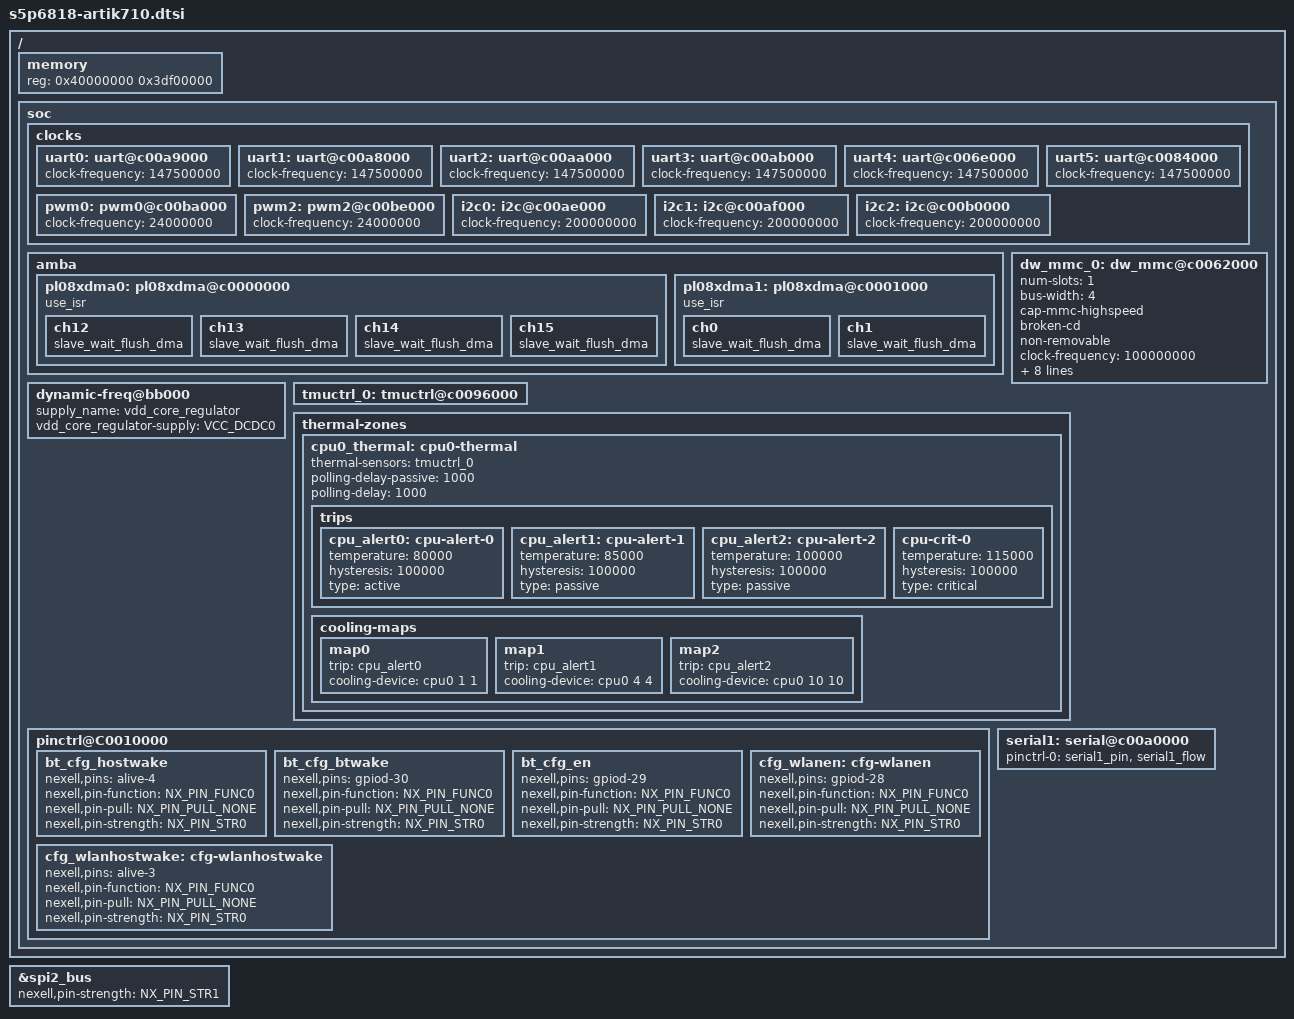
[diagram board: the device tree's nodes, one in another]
/*
 * Copyright (C) 2016  Nexell Co., Ltd.
 * Author: Youngbok, Park <ybpark@nexell.co.kr>
 *
 * This program is free software; you can redistribute it and/or
 * modify it under the terms of the GNU General Public License
 * as published by the Free Software Foundation; either version 2
 * of the License, or (at your option) any later version.
 *
 * This program is distributed in the hope that it will be useful,
 * but WITHOUT ANY WARRANTY; without even the implied warranty of
 * MERCHANTABILITY or FITNESS FOR A PARTICULAR PURPOSE.  See the
 * GNU General Public License for more details.
 *
 * You should have received a copy of the GNU General Public License
 * along with this program.  If not, see <http://www.gnu.org/licenses/>.
 */
/memreserve/ 0x7de00000 0x00100000; /* OP-TEE SHM */
#include <dt-bindings/interrupt-controller/irq.h>
#include "s5p6818.dtsi"

/ {
	memory {
		device_type = "memory";
		reg = <0x40000000 0x3df00000>;
	};

	soc {
		#include "s5p6818-pinctrl.dtsi"

		clocks {
			uart0:uart@c00a9000 { clock-frequency = <147500000>; };
			uart1:uart@c00a8000 { clock-frequency = <147500000>; };
			uart2:uart@c00aa000 { clock-frequency = <147500000>; };
			uart3:uart@c00ab000 { clock-frequency = <147500000>; };
			uart4:uart@c006e000 { clock-frequency = <147500000>; };
			uart5:uart@c0084000 { clock-frequency = <147500000>; };
			pwm0:pwm0@c00ba000 { clock-frequency = <24000000>; };
			pwm2:pwm2@c00be000 { clock-frequency = <24000000>; };
			i2c0:i2c@c00ae000  { clock-frequency = <200000000>; };
			i2c1:i2c@c00af000  { clock-frequency = <200000000>; };
			i2c2:i2c@c00b0000  { clock-frequency = <200000000>; };
		};

		amba {
			pl08xdma0:pl08xdma@c0000000 {
				use_isr;

				ch12 {
					slave_wait_flush_dma;
				};

				ch13 {
					slave_wait_flush_dma;
				};

				ch14 {
					slave_wait_flush_dma;
				};

				ch15 {
					slave_wait_flush_dma;
				};
			};

			pl08xdma1:pl08xdma@c0001000 {
				use_isr;

				ch0 {
					slave_wait_flush_dma;
				};

				ch1 {
					slave_wait_flush_dma;
				};
			};
		};

		dw_mmc_0:dw_mmc@c0062000 {
			num-slots = <1>;
			bus-width = <4>;
			cap-mmc-highspeed;
			broken-cd;
			non-removable;
			clock-frequency = <100000000>;
			card-detect-delay = <200>;
			disable-wp;
			status = "okay";
			nexell,drive_dly = <0x0>;
			nexell,drive_shift = <0x02>;
			nexell,sample_dly = <0x00>;
			nexell,sample_shift = <0x01>;
			disable-data-tag;
			cap-mmc-hw-reset;
		};

		dynamic-freq@bb000 {
			supply_name = "vdd_core_regulator";
			vdd_core_regulator-supply = <&VCC_DCDC0>;
		};

		tmuctrl_0: tmuctrl@c0096000 {
			status = "okay";
		};

		thermal-zones {
			cpu0_thermal: cpu0-thermal {
				thermal-sensors = <&tmuctrl_0>;
				polling-delay-passive = <1000>;
				polling-delay = <1000>;
				trips {
					cpu_alert0: cpu-alert-0 {
						temperature = <80000>;
						hysteresis = <100000>;
						type = "active";
					};
					cpu_alert1: cpu-alert-1 {
						temperature = <85000>;
						hysteresis = <100000>;
						type = "passive";
					};
					cpu_alert2: cpu-alert-2 {
						temperature = <100000>;
						hysteresis = <100000>;
						type = "passive";
					};
					cpu-crit-0 {
						temperature = <115000>;
						hysteresis = <100000>;
						type = "critical";
					};
				};

				cooling-maps {
					map0 {
						trip = <&cpu_alert0>;
						cooling-device = <&cpu0 1 1>;
					};
					map1 {
						trip = <&cpu_alert1>;
						cooling-device = <&cpu0 4 4>;
					};
					map2 {
						trip = <&cpu_alert2>;
						cooling-device = <&cpu0 10 10>;
					};
				};
			};
		};

		pinctrl@C0010000 {
			bt_cfg_hostwake:bt_cfg_hostwake {
				nexell,pins = "alive-4";
				nexell,pin-function = <NX_PIN_FUNC0>;
				nexell,pin-pull = <NX_PIN_PULL_NONE>;
				nexell,pin-strength = <NX_PIN_STR0>;
			};
			bt_cfg_btwake:bt_cfg_btwake {
				nexell,pins = "gpiod-30";
				nexell,pin-function = <NX_PIN_FUNC0>;
				nexell,pin-pull = <NX_PIN_PULL_NONE>;
				nexell,pin-strength = <NX_PIN_STR0>;
			};
			bt_cfg_en:bt_cfg_en {
				nexell,pins = "gpiod-29";
				nexell,pin-function = <NX_PIN_FUNC0>;
				nexell,pin-pull = <NX_PIN_PULL_NONE>;
				nexell,pin-strength = <NX_PIN_STR0>;
			};

			cfg_wlanen: cfg-wlanen {
				nexell,pins ="gpiod-28";
				nexell,pin-function = <NX_PIN_FUNC0>;
				nexell,pin-pull = <NX_PIN_PULL_NONE>;
				nexell,pin-strength = <NX_PIN_STR0>;
			};

			cfg_wlanhostwake: cfg-wlanhostwake {
				nexell,pins = "alive-3";
				nexell,pin-function = <NX_PIN_FUNC0>;
				nexell,pin-pull = <NX_PIN_PULL_NONE>;
				nexell,pin-strength = <NX_PIN_STR0>;
			};
		};

		serial1:serial@c00a0000 {
			status = "okay";
			pinctrl-0 = <&serial1_pin>, <&serial1_flow>;
		};
	};	/*** soc ***/

};

&spi2_bus {
	nexell,pin-strength = <NX_PIN_STR1>;
};
